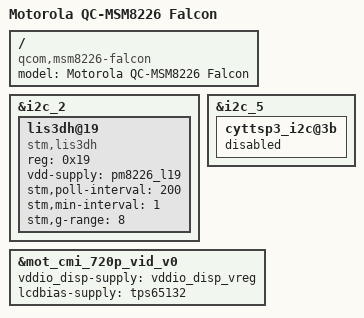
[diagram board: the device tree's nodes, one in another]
/* Copyright (c) 2013, The Linux Foundation. All rights reserved.
 * Copyright (c) 2013 Motorola Mobility LLC
 *
 * This program is free software; you can redistribute it and/or modify
 * it under the terms of the GNU General Public License version 2 and
 * only version 2 as published by the Free Software Foundation.
 *
 * This program is distributed in the hope that it will be useful,
 * but WITHOUT ANY WARRANTY; without even the implied warranty of
 * MERCHANTABILITY or FITNESS FOR A PARTICULAR PURPOSE.  See the
 * GNU General Public License for more details.
 */

/include/ "msm8226-moto-common.dtsi"
/include/ "dsi-panel-mot-cmi-720p-video.dtsi"

/ {
	model = "Motorola QC-MSM8226 Falcon";
	compatible = "qcom,msm8226-falcon",
		     "qcom,msm8226-moto",
		     "qcom,msm8226";
};

&i2c_2 {
	lis3dh@19 {
		compatible = "stm,lis3dh";
		reg = <0x19>;
		vdd-supply = <&pm8226_l19>;
		stm,poll-interval = <200>;
		stm,min-interval = <1>;
		stm,g-range = <8>;
	};
};

&i2c_5 {
	cyttsp3_i2c@3b {
		status = "disabled";
	};
};

&mot_cmi_720p_vid_v0 {
	vddio_disp-supply = <&vddio_disp_vreg>;
	lcdbias-supply = <&tps65132>;
};
